# MB9BF36xx register map
File version: 1.0
Registers are 8-bit, read-write, reset 0x0 unless marked. A register's access mark holds for its fields unless they carry their own. Offsets are from the block's base; [hi:lo] are bit positions; {n}, {i} and the like mark numbered series; 'fields as' and 'values as' point back to an identical list.

## GPIO — peripheral GPIO
Base 0x4006F000
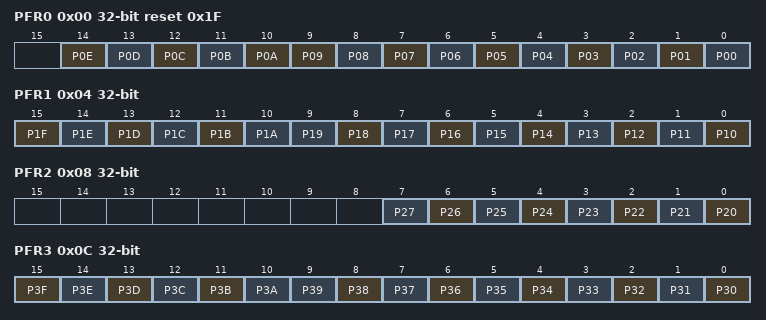
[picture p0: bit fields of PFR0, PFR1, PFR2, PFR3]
0x00 PFR0 32-bit reset 0x1F
  [14] P0E, [13] P0D, [12] P0C, [11] P0B, [10] P0A, [n] P{n:02} (n=0..9)
0x04 PFR1 32-bit
  [15] P1F, [14] P1E, [13] P1D, [12] P1C, [11] P1B, [10] P1A, [n-10] P{n} (n=10..19)
0x08 PFR2 32-bit
  [n-20] P{n} (n=20..27)
0x0C PFR3 32-bit
  [15] P3F, [14] P3E, [13] P3D, [12] P3C, [11] P3B, [10] P3A, [n-30] P{n} (n=30..39)
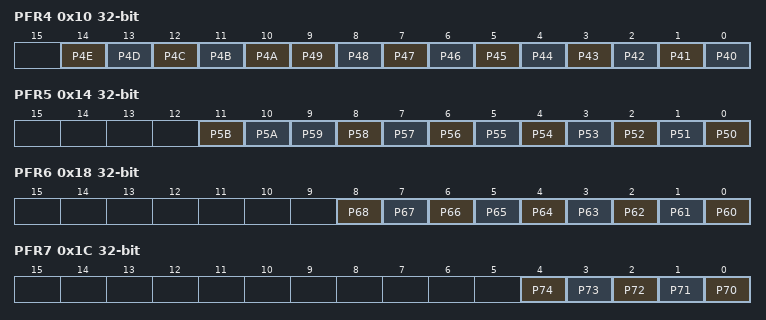
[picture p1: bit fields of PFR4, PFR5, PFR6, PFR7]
0x10 PFR4 32-bit
  [14] P4E, [13] P4D, [12] P4C, [11] P4B, [10] P4A, [n-40] P{n} (n=40..49)
0x14 PFR5 32-bit
  [11] P5B, [10] P5A, [n-50] P{n} (n=50..59)
0x18 PFR6 32-bit
  [n-60] P{n} (n=60..68)
0x1C PFR7 32-bit
  [n-70] P{n} (n=70..74)
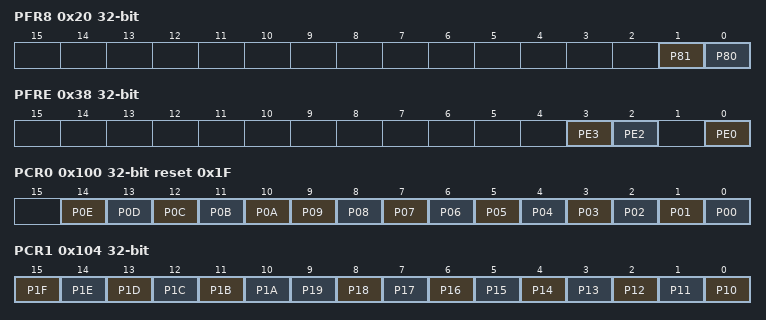
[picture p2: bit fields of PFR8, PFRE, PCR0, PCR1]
0x20 PFR8 32-bit
  [1] P81, [0] P80
0x38 PFRE 32-bit (reset mask 0xB)
  [3] PE3, [2] PE2, [0] PE0
0x100 PCR0 32-bit reset 0x1F
  fields as PFR0
0x104 PCR1 32-bit
  fields as PFR1
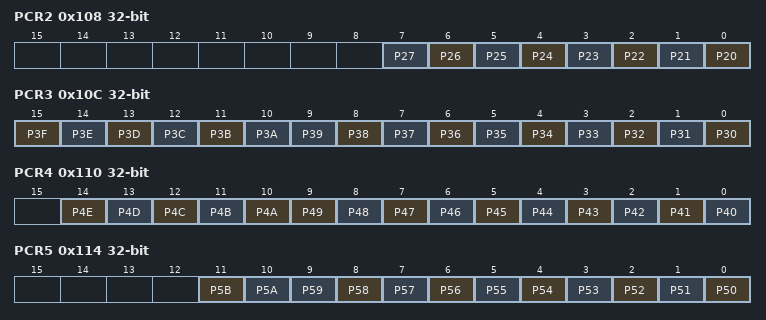
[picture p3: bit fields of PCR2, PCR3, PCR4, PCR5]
0x108 PCR2 32-bit
  [n-20] P{n} (n=20..27)
0x10C PCR3 32-bit
  fields as PFR3
0x110 PCR4 32-bit
  fields as PFR4
0x114 PCR5 32-bit
  [11] P5B, [10] P5A, [n-50] P{n} (n=50..59)
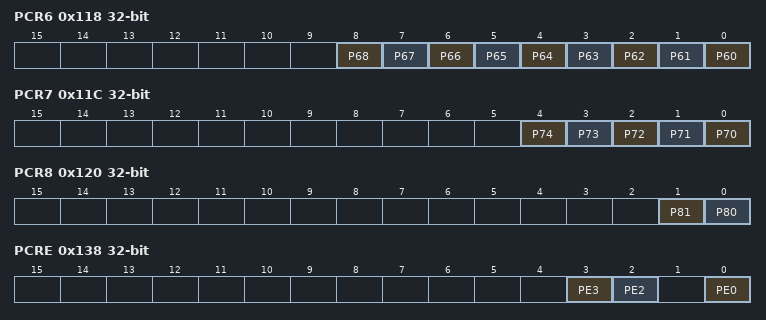
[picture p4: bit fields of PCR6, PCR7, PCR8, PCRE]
0x118 PCR6 32-bit
  [n-60] P{n} (n=60..68)
0x11C PCR7 32-bit
  [n-70] P{n} (n=70..74)
0x120 PCR8 32-bit
  [1] P81, [0] P80
0x138 PCRE 32-bit (reset mask 0xB)
  [3] PE3, [2] PE2, [0] PE0
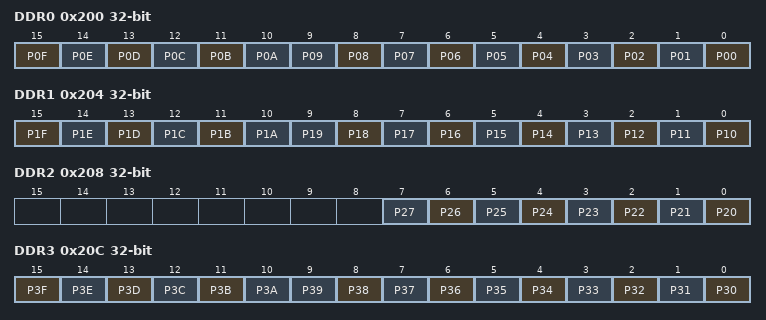
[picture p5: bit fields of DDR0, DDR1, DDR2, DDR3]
0x200 DDR0 32-bit
  [15] P0F, [14] P0E, [13] P0D, [12] P0C, [11] P0B, [10] P0A, [n] P{n:02} (n=0..9)
0x204 DDR1 32-bit
  fields as PFR1
0x208 DDR2 32-bit
  [n-20] P{n} (n=20..27)
0x20C DDR3 32-bit
  fields as PFR3
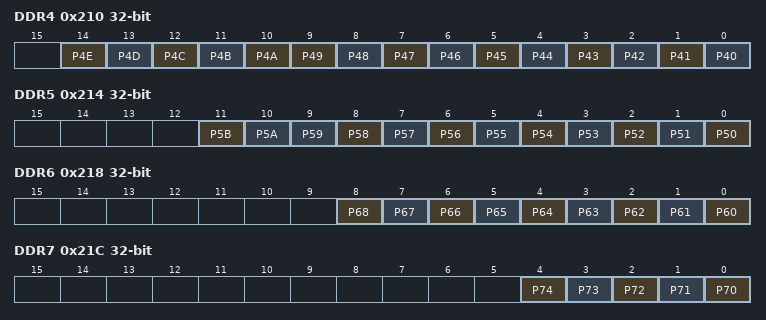
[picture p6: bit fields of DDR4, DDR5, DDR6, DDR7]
0x210 DDR4 32-bit
  fields as PFR4
0x214 DDR5 32-bit
  [11] P5B, [10] P5A, [n-50] P{n} (n=50..59)
0x218 DDR6 32-bit
  [n-60] P{n} (n=60..68)
0x21C DDR7 32-bit
  [n-70] P{n} (n=70..74)
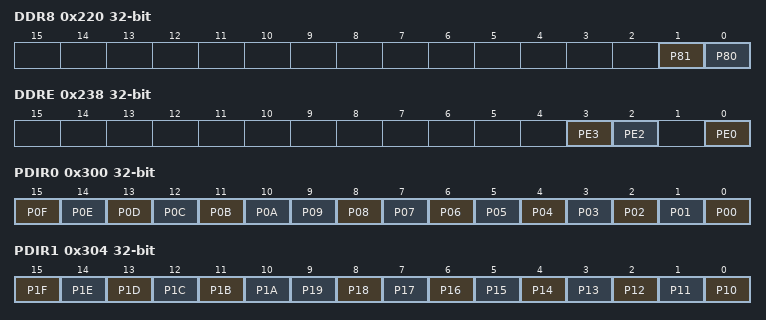
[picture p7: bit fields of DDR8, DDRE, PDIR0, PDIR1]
0x220 DDR8 32-bit
  [1] P81, [0] P80
0x238 DDRE 32-bit (reset mask 0xB)
  [3] PE3, [2] PE2, [0] PE0
0x300 PDIR0 32-bit
  fields as DDR0
0x304 PDIR1 32-bit
  fields as PFR1
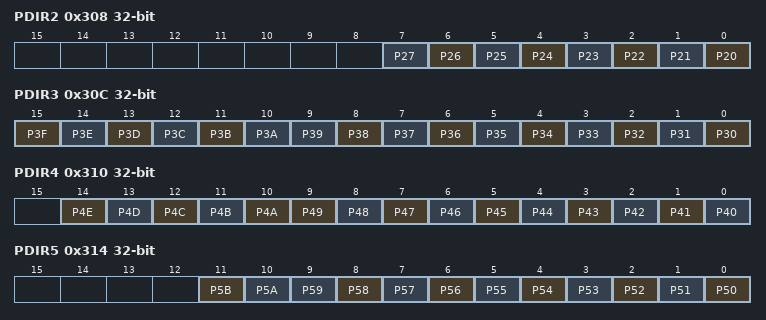
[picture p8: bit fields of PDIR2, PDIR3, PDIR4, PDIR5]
0x308 PDIR2 32-bit
  [n-20] P{n} (n=20..27)
0x30C PDIR3 32-bit
  fields as PFR3
0x310 PDIR4 32-bit
  fields as PFR4
0x314 PDIR5 32-bit
  [11] P5B, [10] P5A, [n-50] P{n} (n=50..59)
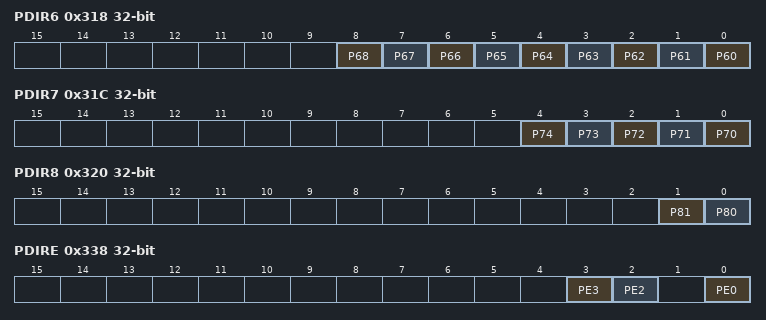
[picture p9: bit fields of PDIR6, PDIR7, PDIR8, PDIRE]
0x318 PDIR6 32-bit
  [n-60] P{n} (n=60..68)
0x31C PDIR7 32-bit
  [n-70] P{n} (n=70..74)
0x320 PDIR8 32-bit
  [1] P81, [0] P80
0x338 PDIRE 32-bit (reset mask 0xB)
  [3] PE3, [2] PE2, [0] PE0
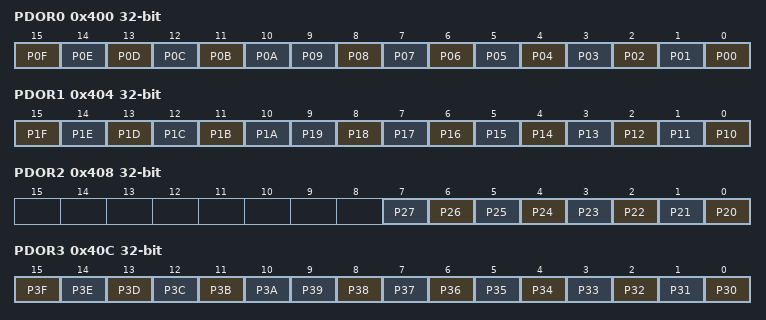
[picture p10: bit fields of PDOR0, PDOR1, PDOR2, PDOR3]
0x400 PDOR0 32-bit
  fields as DDR0
0x404 PDOR1 32-bit
  fields as PFR1
0x408 PDOR2 32-bit
  [n-20] P{n} (n=20..27)
0x40C PDOR3 32-bit
  fields as PFR3
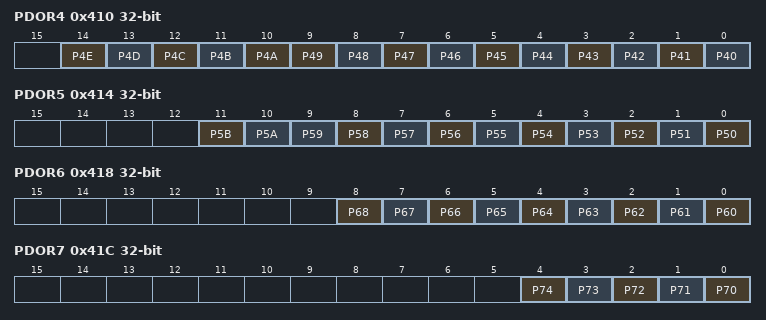
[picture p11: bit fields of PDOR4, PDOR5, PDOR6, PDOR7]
0x410 PDOR4 32-bit
  fields as PFR4
0x414 PDOR5 32-bit
  [11] P5B, [10] P5A, [n-50] P{n} (n=50..59)
0x418 PDOR6 32-bit
  [n-60] P{n} (n=60..68)
0x41C PDOR7 32-bit
  [n-70] P{n} (n=70..74)
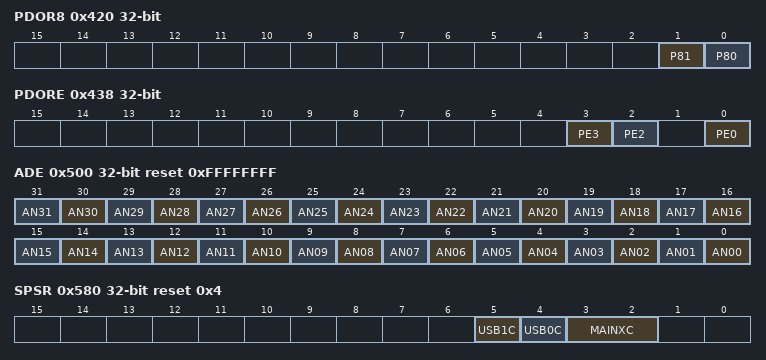
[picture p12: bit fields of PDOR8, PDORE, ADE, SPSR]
0x420 PDOR8 32-bit
  [1] P81, [0] P80
0x438 PDORE 32-bit (reset mask 0xB)
  [3] PE3, [2] PE2, [0] PE0
0x500 ADE 32-bit reset 0xFFFFFFFF
  [n] AN{n:02} (n=0..31)
0x580 SPSR 32-bit reset 0x4
  [5] USB1C, [4] USB0C, [3:2] MAINXC
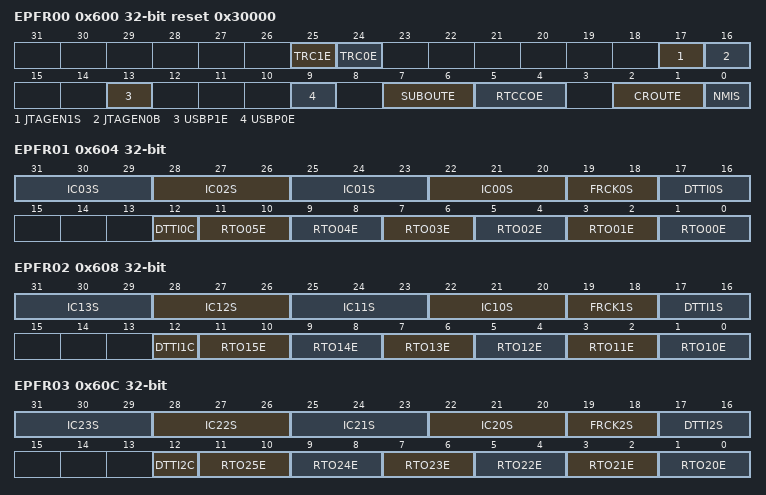
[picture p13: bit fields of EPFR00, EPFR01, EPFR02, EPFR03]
0x600 EPFR00 32-bit reset 0x30000
  [25] TRC1E, [24] TRC0E, [17] JTAGEN1S, [16] JTAGEN0B, [13] USBP1E, [9] USBP0E, [7:6] SUBOUTE, [5:4] RTCCOE, [2:1] CROUTE, [0] NMIS
0x604 EPFR01 32-bit
  [3n+22:3n+20] IC{n:02}S (n=0..3), [19:18] FRCK0S, [17:16] DTTI0S, [12] DTTI0C, [2n+1:2n] RTO{n:02}E (n=0..5)
0x608 EPFR02 32-bit
  [3n-8:3n-10] IC{n}S (n=10..13), [19:18] FRCK1S, [17:16] DTTI1S, [12] DTTI1C, [2n-19:2n-20] RTO{n}E (n=10..15)
0x60C EPFR03 32-bit
  [3n-38:3n-40] IC{n}S (n=20..23), [19:18] FRCK2S, [17:16] DTTI2S, [12] DTTI2C, [2n-39:2n-40] RTO{n}E (n=20..25)
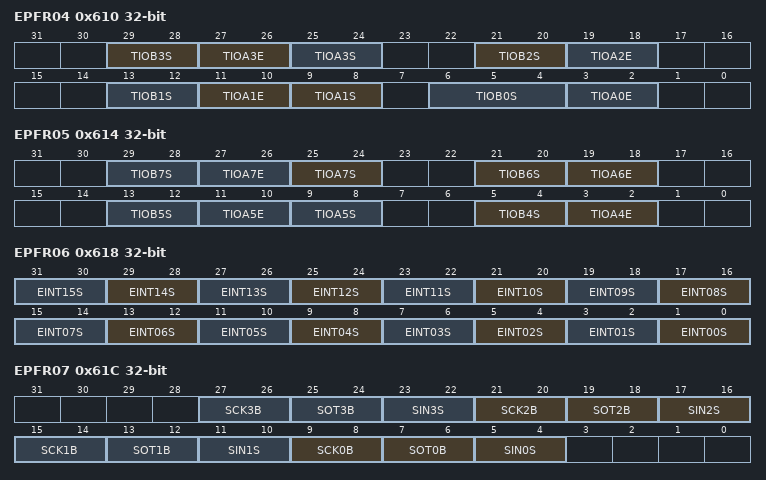
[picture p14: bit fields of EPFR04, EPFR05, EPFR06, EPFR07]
0x610 EPFR04 32-bit
  [29:28] TIOB3S, [8n+3:8n+2] TIOA{n}E (n=0..3), [25:24] TIOA3S, [21:20] TIOB2S, [13:12] TIOB1S, [9:8] TIOA1S, [6:4] TIOB0S
0x614 EPFR05 32-bit
  [8n-27:8n-28] TIOB{n}S (n=4..7), [8n-29:8n-30] TIOA{n}E (n=4..7), [25:24] TIOA7S, [9:8] TIOA5S
0x618 EPFR06 32-bit
  [2n+1:2n] EINT{n:02}S (n=0..15)
0x61C EPFR07 32-bit
  [6n+9:6n+8] SCK{n}B (n=0..3), [6n+7:6n+6] SOT{n}B (n=0..3), [6n+5:6n+4] SIN{n}S (n=0..3)
0x620 EPFR08 32-bit
  [31:30] CTS5S, [29:28] RTS5E, [6n-15:6n-16] SCK{n}B (n=4..7), [6n-17:6n-18] SOT{n}B (n=4..7), [6n-19:6n-20] SIN{n}S (n=4..7), [3:2] CTS4S, [1:0] RTS4E
0x624 EPFR09 32-bit
  [31:30] CTX1E, [29:28] CRX1S, [27:26] CTX0E, [25:24] CRX0S, [23:20] ADTRG2S, [19:16] ADTRG1S, [15:12] ADTRG0S, [11:10] QZIN1S, [9:8] QBIN1S, [7:6] QAIN1S, [5:4] QZIN0S, [3:2] QBIN0S, [1:0] QAIN0S
0x628 EPFR10 32-bit
  [n+7] UEA{n:02}E (n=8..24), [14] UEAOOE, [n+6] UECS{n}E (n=1..7), [6] UEFLSE, [5] UEOEXE, [4] UEDQME, [3] UEWEXE, [2] UECLKE, [1] UEDTHB, [0] UEDEFB
0x62C EPFR11 32-bit
  [25] UERLC, [n+9] UED{n:02}B (n=0..15), [n+1] UEA{n:02}E (n=1..7), [1] UECS0E, [0] UEALEE
0x630 EPFR12 32-bit
  [8n-59:8n-60] TIOB{n}S (n=8..11), [8n-61:8n-62] TIOA{n}E (n=8..11), [25:24] TIOA11S, [9:8] TIOA9S
0x634 EPFR13 32-bit
  [8n-91:8n-92] TIOB{n}S (n=12..15), [8n-93:8n-94] TIOA{n}E (n=12..15), [25:24] TIOA15S, [9:8] TIOA13S
0x638 EPFR14 32-bit
  [29:28] E_SPLC, [27] E_PSE, [26] E_CKE, [25] E_MD1B, [24] E_MD0B, [23] E_MC1B, [22] E_MC0E, [21] E_TE1E, [20] E_TE0E, [19] E_TD1E, [18] E_TD0E, [5:4] QZIN2S, [3:2] QBIN2S, [1:0] QAIN2S
0x63C EPFR15 32-bit
  [2n-31:2n-32] EINT{n}S (n=16..31)
0x640 EPFR16 32-bit
  [29] SFMPBC, [28] SFMPAC, [6n-39:6n-40] SCK{n}B (n=8..11), [6n-41:6n-42] SOT{n}B (n=8..11), [6n-43:6n-44] SIN{n}S (n=8..11), [3:2] SCS7B, [1:0] SCS6B
0x644 EPFR17 32-bit
  [6n-63:6n-64] SCK{n}B (n=12..15), [6n-65:6n-66] SOT{n}B (n=12..15), [6n-67:6n-68] SIN{n}S (n=12..15)
0x648 EPFR18 32-bit
  [29:28] SDWPS, [27:26] SDCDS, [2n+19:2n+18] SDDATA{n}B (n=0..3), [17:16] SDCMDB, [15:14] SDCLKE, [9:8] QZIN3S, [7:6] QBIN3S, [5:4] QAIN3S
0x64C EPFR19 32-bit reset not defined
0x650 EPFR20 32-bit
  [n-7] UED{n}B (n=16..31), [8] UEDTHHB, [7] UEDQM3E, [6] UEDQM2E, [5] UECSXE, [4] UEDWEXE, [3] UECASE, [2] UERASE, [1] UESMCEE, [0] UESMCKE
0x700 PZR0 32-bit
  fields as DDR0
0x704 PZR1 32-bit
  fields as PFR1
0x708 PZR2 32-bit
  [n-20] P{n} (n=20..27)
0x70C PZR3 32-bit
  fields as PFR3
0x710 PZR4 32-bit
  fields as PFR4
0x714 PZR5 32-bit
  [11] P5B, [10] P5A, [n-50] P{n} (n=50..59)
0x718 PZR6 32-bit
  [n-60] P{n} (n=60..68)
0x71C PZR7 32-bit
  [n-70] P{n} (n=70..74)
0x720 PZR8 32-bit
  [1] P81, [0] P80
0x738 PZRE 32-bit (reset mask 0xB)
  [3] PE3, [2] PE2, [0] PE0

## Notices in the file
Licence Terms
FUJITSU SEMICONDUCTOR LIMITED (gLICENSORh) hereby grants and
you (gLICENSEEh) hereby accept a non transferable, non-exclusive
licence to use and copy the deliverables (gDeliverablesh) solely for
the purpose of; (i) developing LICENSEEfs development tools and
distributing such development tools to third parties; (ii) generating
derivative representations of the Deliverables to develop and debug
software for LICENSORfs targeted devices or device series identified
within the Deliverables, (together the gPurposeh) under the following
terms and conditions:
1. Ownership.
The Deliverables are the property of LICENSOR. LICENSEE acquires no
right, title or interest in the Deliverables other than the licence
rights granted herein.
2. Use.
LICENSEE shall only be permitted to use the Deliverables for the
Purpose. LICENSEE shall not reverse engineer, decompile or
disassemble the Deliverables, in whole or in part.
3. Copies.
All copies of the Deliverables must bear the same notice(s) contained
on the original copies of the Deliverables.
4. No Warranty.
THE DELIVERABLES ARE PROVIDED gAS ISh AND ANY EXPRESS, IMPLIED OR
STATUTORY WARRANTIES, INCLUDING, BUT NOT LIMITED TO, THE IMPLIED
WARRANTIES OF MERCHANTABILITY, SATISFACTORY QUALITY AND FITNESS FOR
A PARTICULAR PURPOSE ARE DISCLAIMED.
IN NO EVENT SHALL LICENSOR BE LIABLE FOR ANY DIRECT, INDIRECT,
INCIDENTAL, SPECIAL, EXEMPLARY, OR CONSEQUENTIAL DAMAGES HOWEVER CAUSED
AND ON ANY THEORY OF LIABILITY, WHETHER IN CONTRACT, STRICT LIABILITY,
OR TORT (INCLUDING NEGLIGENCE OR OTHERWISE) ARISING IN ANY WAY OUT OF
THE USE OF THE DELIVERABLES, EVEN IF ADVISED OF THE POSSIBILITY OF SUCH
DAMAGE.
LICENSEE EXPRESSLY ASSUMES ALL LIABILITIES AND RISKS, FOR USE OR
OPERATION OF THE DELIVERABLES.
5.In the event that LICENSEE receives early access to the Deliverables,
LICENSEE acknowledges and agrees that;
(a) notwithstanding the licence grants above, LICENSEE shall only be
permitted to use the Deliverables solely internally for evaluation and
providing feedback to LICENSOR;
(b) except with respect to the limited licence grants in 5(a), LICENSEE
shall be subject to all of the terms and conditions set out above; and
(c) the Deliverables are confidential information and LICENSEE shall
maintain in confidence the Deliverables and apply security measures no
less stringent than the measures that LICENSEE applies to its own like
information, but not less than a reasonable degree of care, to prevent
unauthorised disclosure and use of the Deliverables.
